AUTOSAR XML (schema 4-0-3)
standard types defined: UInt16
package /AUTOSAR_Platform/DataConstrs
  range DC_UInt16: raw 0..65535
package /PATAC/EEPROM/BaseType
  base type PJB_UInt16: category=FIXED_LENGTH, base-type-size=16, base-type-encoding=NONE, native-declaration=unsigned short
package /PATAC/EEPROM/ImplementationDataType
  impl type EEP_Uint16: category=VALUE, base-type=PJB_UInt16, sw-calibration-access=READ-ONLY, type-emitter=RTE
package /PATAC/MSM/ComponentTypes
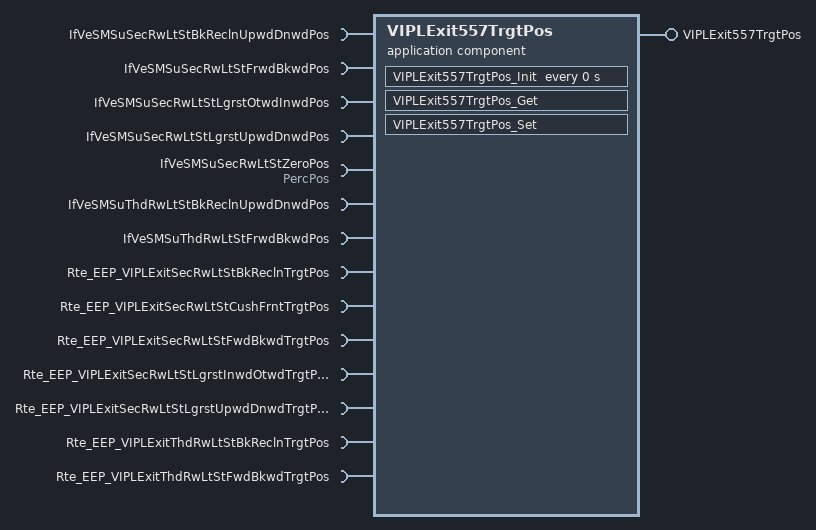
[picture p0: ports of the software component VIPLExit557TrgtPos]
  application sw component type VIPLExit557TrgtPos
    provide port VIPLExit557TrgtPos: provided-com-specs=[{operation=VIPLExit557TrgtPos/Get, queue-length=1}, {operation=VIPLExit557TrgtPos/Set, queue-length=1}], provided-interface=VIPLExit557TrgtPos
    14 x require port:
      IfVeSMSuSecRwLtStBkReclnUpwdDnwdPos: nonqueued-receiver-com-spec{data-element=IfVeSMSuSecRwLtStBkReclnUpwdDnwdPos/Val, filter=data-filter-type=ALWAYS, init-value=0}, required-interface=IfVeSMSuSecRwLtStBkReclnUpwdDnwdPos
      IfVeSMSuSecRwLtStFrwdBkwdPos: nonqueued-receiver-com-spec{data-element=IfVeSMSuSecRwLtStFrwdBkwdPos/Val, filter=data-filter-type=ALWAYS, init-value=0}, required-interface=IfVeSMSuSecRwLtStFrwdBkwdPos
      IfVeSMSuSecRwLtStLgrstOtwdInwdPos: nonqueued-receiver-com-spec{data-element=IfVeSMSuSecRwLtStLgrstOtwdInwdPos/Val, filter=data-filter-type=ALWAYS, init-value=0}, required-interface=IfVeSMSuSecRwLtStLgrstOtwdInwdPos
      IfVeSMSuSecRwLtStLgrstUpwdDnwdPos: nonqueued-receiver-com-spec{data-element=IfVeSMSuSecRwLtStLgrstUpwdDnwdPos/Val, filter=data-filter-type=ALWAYS, init-value=0}, required-interface=IfVeSMSuSecRwLtStLgrstUpwdDnwdPos
      IfVeSMSuSecRwLtStZeroPos: nonqueued-receiver-com-spec{data-element=PercPos/Val, filter=data-filter-type=ALWAYS, init-value=0}, required-interface=PercPos
      IfVeSMSuThdRwLtStBkReclnUpwdDnwdPos: nonqueued-receiver-com-spec{data-element=IfVeSMSuThdRwLtStBkReclnUpwdDnwdPos/Val, filter=data-filter-type=ALWAYS, init-value=0}, required-interface=IfVeSMSuThdRwLtStBkReclnUpwdDnwdPos
      IfVeSMSuThdRwLtStFrwdBkwdPos: nonqueued-receiver-com-spec{data-element=IfVeSMSuThdRwLtStFrwdBkwdPos/Val, filter=data-filter-type=ALWAYS, init-value=0}, required-interface=IfVeSMSuThdRwLtStFrwdBkwdPos
      Rte_EEP_VIPLExitSecRwLtStBkReclnTrgtPos: required-com-specs=[Rte_EEP_VIPLExitSecRwLtStBkReclnTrgtPos/Get, Rte_EEP_VIPLExitSecRwLtStBkReclnTrgtPos/Set], required-interface=Rte_EEP_VIPLExitSecRwLtStBkReclnTrgtPos
      Rte_EEP_VIPLExitSecRwLtStCushFrntTrgtPos: required-com-specs=[Rte_EEP_VIPLExitSecRwLtStCushFrntTrgtPos/Get, Rte_EEP_VIPLExitSecRwLtStCushFrntTrgtPos/Set], required-interface=Rte_EEP_VIPLExitSecRwLtStCushFrntTrgtPos
      Rte_EEP_VIPLExitSecRwLtStFwdBkwdTrgtPos: required-com-specs=[Rte_EEP_VIPLExitSecRwLtStFwdBkwdTrgtPos/Get, Rte_EEP_VIPLExitSecRwLtStFwdBkwdTrgtPos/Set], required-interface=Rte_EEP_VIPLExitSecRwLtStFwdBkwdTrgtPos
      Rte_EEP_VIPLExitSecRwLtStLgrstInwdOtwdTrgtPos: required-com-specs=[Rte_EEP_VIPLExitSecRwLtStLgrstInwdOtwdTrgtPos/Get, Rte_EEP_VIPLExitSecRwLtStLgrstInwdOtwdTrgtPos/Set], required-interface=Rte_EEP_VIPLExitSecRwLtStLgrstInwdOtwdTrgtPos
      Rte_EEP_VIPLExitSecRwLtStLgrstUpwdDnwdTrgtPos: required-com-specs=[Rte_EEP_VIPLExitSecRwLtStLgrstUpwdDnwdTrgtPos/Get, Rte_EEP_VIPLExitSecRwLtStLgrstUpwdDnwdTrgtPos/Set], required-interface=Rte_EEP_VIPLExitSecRwLtStLgrstUpwdDnwdTrgtPos
      Rte_EEP_VIPLExitThdRwLtStBkReclnTrgtPos: required-com-specs=[Rte_EEP_VIPLExitThdRwLtStBkReclnTrgtPos/Get, Rte_EEP_VIPLExitThdRwLtStBkReclnTrgtPos/Set], required-interface=Rte_EEP_VIPLExitThdRwLtStBkReclnTrgtPos
      Rte_EEP_VIPLExitThdRwLtStFwdBkwdTrgtPos: required-com-specs=[Rte_EEP_VIPLExitThdRwLtStFwdBkwdTrgtPos/Get, Rte_EEP_VIPLExitThdRwLtStFwdBkwdTrgtPos/Set], required-interface=Rte_EEP_VIPLExitThdRwLtStFwdBkwdTrgtPos
    behavior VIPLExit557TrgtPos_InternalBehavior
      operation invoked event OIT_VIPLExit557TrgtPos_Get_VIPLExit557TrgtPos_Get: start-on-event=VIPLExit557TrgtPos_Get, operation=VIPLExit557TrgtPos.Get
      timing event VIPLExit557TrgtPos_InitEvent: start-on-event=VIPLExit557TrgtPos_Init, period=0
      operation invoked event OIT_VIPLExit557TrgtPos_Set_VIPLExit557TrgtPos_Set: start-on-event=VIPLExit557TrgtPos_Set, operation=VIPLExit557TrgtPos.Set
      runnable VIPLExit557TrgtPos_Get
        7 x sync call, all with timeout=0:
          SC_Rte_EEP_VIPLExitSecRwLtStBkReclnTrgtPos_Get: operation=Rte_EEP_VIPLExitSecRwLtStBkReclnTrgtPos.Get
          SC_Rte_EEP_VIPLExitSecRwLtStCushFrntTrgtPos_Get: operation=Rte_EEP_VIPLExitSecRwLtStCushFrntTrgtPos.Get
          SC_Rte_EEP_VIPLExitSecRwLtStFwdBkwdTrgtPos_Get: operation=Rte_EEP_VIPLExitSecRwLtStFwdBkwdTrgtPos.Get
          SC_Rte_EEP_VIPLExitSecRwLtStLgrstInwdOtwdTrgtPos_Get: operation=Rte_EEP_VIPLExitSecRwLtStLgrstInwdOtwdTrgtPos.Get
          SC_Rte_EEP_VIPLExitSecRwLtStLgrstUpwdDnwdTrgtPos_Get: operation=Rte_EEP_VIPLExitSecRwLtStLgrstUpwdDnwdTrgtPos.Get
          SC_Rte_EEP_VIPLExitThdRwLtStBkReclnTrgtPos_Get: operation=Rte_EEP_VIPLExitThdRwLtStBkReclnTrgtPos.Get
          SC_Rte_EEP_VIPLExitThdRwLtStFwdBkwdTrgtPos_Get: operation=Rte_EEP_VIPLExitThdRwLtStFwdBkwdTrgtPos.Get
      runnable VIPLExit557TrgtPos_Init
      runnable VIPLExit557TrgtPos_Set
        data-receive-point-by-arguments:
          7 x access:
            REC_IfVeSMSuSecRwLtStBkReclnUpwdDnwdPos_Val: accessed-variable=IfVeSMSuSecRwLtStBkReclnUpwdDnwdPos.Val
            REC_IfVeSMSuSecRwLtStFrwdBkwdPos_Val: accessed-variable=IfVeSMSuSecRwLtStFrwdBkwdPos.Val
            REC_IfVeSMSuSecRwLtStLgrstOtwdInwdPos_Val: accessed-variable=IfVeSMSuSecRwLtStLgrstOtwdInwdPos.Val
            REC_IfVeSMSuSecRwLtStLgrstUpwdDnwdPos_Val: accessed-variable=IfVeSMSuSecRwLtStLgrstUpwdDnwdPos.Val
            REC_IfVeSMSuSecRwLtStZeroPos_Val: accessed-variable=IfVeSMSuSecRwLtStZeroPos.Val
            REC_IfVeSMSuThdRwLtStBkReclnUpwdDnwdPos_Val: accessed-variable=IfVeSMSuThdRwLtStBkReclnUpwdDnwdPos.Val
            REC_IfVeSMSuThdRwLtStFrwdBkwdPos_Val: accessed-variable=IfVeSMSuThdRwLtStFrwdBkwdPos.Val
        7 x sync call, all with timeout=0:
          SC_Rte_EEP_VIPLExitSecRwLtStBkReclnTrgtPos_Set: operation=Rte_EEP_VIPLExitSecRwLtStBkReclnTrgtPos.Set
          SC_Rte_EEP_VIPLExitSecRwLtStCushFrntTrgtPos_Set: operation=Rte_EEP_VIPLExitSecRwLtStCushFrntTrgtPos.Set
          SC_Rte_EEP_VIPLExitSecRwLtStFwdBkwdTrgtPos_Set: operation=Rte_EEP_VIPLExitSecRwLtStFwdBkwdTrgtPos.Set
          SC_Rte_EEP_VIPLExitSecRwLtStLgrstInwdOtwdTrgtPos_Set: operation=Rte_EEP_VIPLExitSecRwLtStLgrstInwdOtwdTrgtPos.Set
          SC_Rte_EEP_VIPLExitSecRwLtStLgrstUpwdDnwdTrgtPos_Set: operation=Rte_EEP_VIPLExitSecRwLtStLgrstUpwdDnwdTrgtPos.Set
          SC_Rte_EEP_VIPLExitThdRwLtStBkReclnTrgtPos_Set: operation=Rte_EEP_VIPLExitThdRwLtStBkReclnTrgtPos.Set
          SC_Rte_EEP_VIPLExitThdRwLtStFwdBkwdTrgtPos_Set: operation=Rte_EEP_VIPLExitThdRwLtStFwdBkwdTrgtPos.Set
  swc implementation VIPLExit557TrgtPos_Implementation: behavior=VIPLExit557TrgtPos_InternalBehavior
    code-descriptors:
      code Default: artifact-descriptors=autosar-engineering-object={short-label=Default, category=SWSRC}
package /PATAC/MSM/ModeAdjust/PortInterface
  client server interface VIPLExit557TrgtPos
    operation Get
      7 x arg, all with type=UInt16, direction=OUT, server-argument-impl-policy=USE-ARGUMENT-TYPE:
        SecRwLtStBkReclnTrgtPos
        SecRwLtStZeroTrgtPos
        SecRwLtStLgrstUpwdDnwdTrgtPos
        SecRwLtStLgrstInwdOtwdTrgtPos
        ThdRwLtStBkReclnTrgtPos
        ThdRwLtStFwdBkwdTrgtPos
        SecRwLtStFwdBkwdTrgtPos
    operation Set
  sender receiver interface PercPos: invalidation-policy{data-element=PercPos/Val, handle-invalid=DONT-INVALIDATE}
    data Val: type=UInt16
package /PATAC/MSM/PortInterfaces
  6 x sender receiver interface:
    IfVeSMSuSecRwLtStBkReclnUpwdDnwdPos: invalidation-policy{data-element=IfVeSMSuSecRwLtStBkReclnUpwdDnwdPos/Val, handle-invalid=DONT-INVALIDATE}
      data Val: type=UInt16
    IfVeSMSuSecRwLtStFrwdBkwdPos: invalidation-policy{data-element=IfVeSMSuSecRwLtStFrwdBkwdPos/Val, handle-invalid=DONT-INVALIDATE}
      data Val: type=UInt16
    IfVeSMSuSecRwLtStLgrstOtwdInwdPos: invalidation-policy{data-element=IfVeSMSuSecRwLtStLgrstOtwdInwdPos/Val, handle-invalid=DONT-INVALIDATE}
      data Val: type=UInt16
    IfVeSMSuSecRwLtStLgrstUpwdDnwdPos: invalidation-policy{data-element=IfVeSMSuSecRwLtStLgrstUpwdDnwdPos/Val, handle-invalid=DONT-INVALIDATE}
      data Val: type=UInt16
    IfVeSMSuThdRwLtStBkReclnUpwdDnwdPos: invalidation-policy{data-element=IfVeSMSuThdRwLtStBkReclnUpwdDnwdPos/Val, handle-invalid=DONT-INVALIDATE}
      data Val: type=UInt16
    IfVeSMSuThdRwLtStFrwdBkwdPos: invalidation-policy{data-element=IfVeSMSuThdRwLtStFrwdBkwdPos/Val, handle-invalid=DONT-INVALIDATE}
      data Val: type=UInt16
package /PortInterfaces
  7 x client server interface:
    Rte_EEP_VIPLExitSecRwLtStBkReclnTrgtPos
      operation Get
        arg arg: type=EEP_Uint16, direction=OUT, server-argument-impl-policy=USE-ARGUMENT-TYPE
      operation Set
        arg arg: type=EEP_Uint16, direction=IN, server-argument-impl-policy=USE-ARGUMENT-TYPE
    Rte_EEP_VIPLExitSecRwLtStCushFrntTrgtPos
      operation Get
        arg arg: type=EEP_Uint16, direction=OUT, server-argument-impl-policy=USE-ARGUMENT-TYPE
      operation Set
        arg arg: type=EEP_Uint16, direction=IN, server-argument-impl-policy=USE-ARGUMENT-TYPE
    Rte_EEP_VIPLExitSecRwLtStFwdBkwdTrgtPos
      operation Get
        arg arg: type=EEP_Uint16, direction=OUT, server-argument-impl-policy=USE-ARGUMENT-TYPE
      operation Set
        arg arg: type=EEP_Uint16, direction=IN, server-argument-impl-policy=USE-ARGUMENT-TYPE
    Rte_EEP_VIPLExitSecRwLtStLgrstInwdOtwdTrgtPos
      operation Get
        arg arg: type=EEP_Uint16, direction=OUT, server-argument-impl-policy=USE-ARGUMENT-TYPE
      operation Set
        arg arg: type=EEP_Uint16, direction=IN, server-argument-impl-policy=USE-ARGUMENT-TYPE
    Rte_EEP_VIPLExitSecRwLtStLgrstUpwdDnwdTrgtPos
      operation Get
        arg arg: type=EEP_Uint16, direction=OUT, server-argument-impl-policy=USE-ARGUMENT-TYPE
      operation Set
        arg arg: type=EEP_Uint16, direction=IN, server-argument-impl-policy=USE-ARGUMENT-TYPE
    Rte_EEP_VIPLExitThdRwLtStBkReclnTrgtPos
      operation Get
        arg arg: type=EEP_Uint16, direction=OUT, server-argument-impl-policy=USE-ARGUMENT-TYPE
      operation Set
        arg arg: type=EEP_Uint16, direction=IN, server-argument-impl-policy=USE-ARGUMENT-TYPE
    Rte_EEP_VIPLExitThdRwLtStFwdBkwdTrgtPos
      operation Get
        arg arg: type=EEP_Uint16, direction=OUT, server-argument-impl-policy=USE-ARGUMENT-TYPE
      operation Set
        arg arg: type=EEP_Uint16, direction=IN, server-argument-impl-policy=USE-ARGUMENT-TYPE
